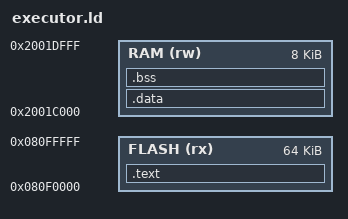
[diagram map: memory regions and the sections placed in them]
/*
 * executor.ld — размещение блоба-исполнителя ВНУТРИ образа приложения chip1.
 *
 * Блоб живёт в свободной (стёртой, 0xFF) области флеша приложения и вызывается
 * родным кодом через перехваченный указатель vtable process-manager. Своего
 * reset-вектора/стартапа НЕТ — поэтому:
 *   - никакой инициализируемой .data (нечем копировать из флеша);
 *   - .bss НЕ обнуляется автоматически => весь стейт инициализируется явно
 *     в mx_executor_init/mx_hook_install (код на это не полагается неявно).
 *
 * [H] Базовые адреса — подтвердить перед заливкой: область флеша должна быть
 * свободна в стоковом образе (проверяет упаковщик tools/pack_snk_mb.py), а
 * RAM-регион — не пересекаться с родным использованием (SP init 0x20016ed8).
 */
ENTRY(mx_hook_entry)

MEMORY
{
    FLASH (rx) : ORIGIN = 0x080F0000, LENGTH = 64K   /* [H] свободная флеш app */
    RAM   (rw) : ORIGIN = 0x2001C000, LENGTH = 8K    /* [H] свободная SRAM */
}

SECTIONS
{
    .text :
    {
        KEEP(*(.text.mx_hook_entry))
        *(.text*)
        *(.rodata*)
        . = ALIGN(4);
    } > FLASH

    /* Ненулевых статических инициализаторов быть не должно (нет стартапа для
     * копирования .data из флеша). Пустоту .data проверяем по arm-none-eabi-size
     * (секция data должна быть 0). */
    .data : { *(.data*) } > RAM

    .bss (NOLOAD) :
    {
        *(.bss*)
        *(COMMON)
        . = ALIGN(4);
    } > RAM

    /DISCARD/ : { *(.ARM.exidx*) *(.comment) }
}
